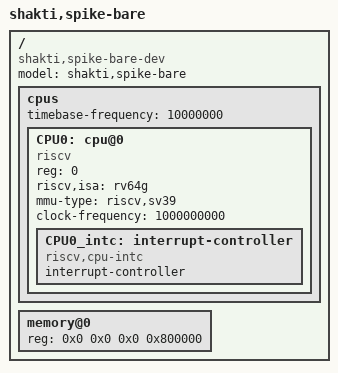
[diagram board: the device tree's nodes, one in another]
/dts-v1/;

/ {
  #address-cells = <1>;
  #size-cells = <1>;
  compatible = "shakti,spike-bare-dev";
  model = "shakti,spike-bare";
  cpus {
    #address-cells = <1>;
    #size-cells = <0>;
    timebase-frequency = <10000000>;
    CPU0: cpu@0 {
      device_type = "cpu";
      reg = <0>;
      status = "okay";
      compatible = "riscv";
      riscv,isa = "rv64g";
      mmu-type = "riscv,sv39";
      clock-frequency = <1000000000>;
      CPU0_intc: interrupt-controller {
        #interrupt-cells = <1>;
        interrupt-controller;
        compatible = "riscv,cpu-intc";
      };
    };
  };
  memory@0 {
    device_type = "memory";
    reg = <0x0 0x0 0x0 0x800000>;
  };

};
